VERSION ""

NS_ :

BS_:

BU_:
VAL_TABLE_ Write_Success 1 "Success" 0 "Not Written" ;
VAL_TABLE_ Read_Write 1 "Write" 0 "Read" ;

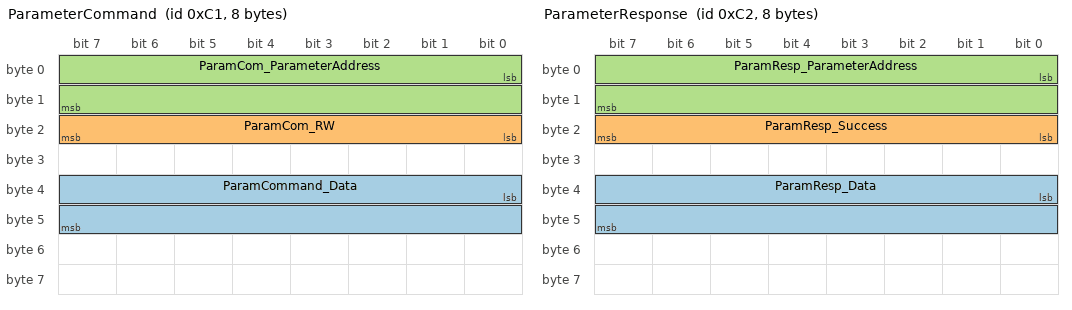
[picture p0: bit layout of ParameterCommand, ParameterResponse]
BO_ 193 ParameterCommand: 8 Vector__XXX
 SG_ ParamCommand_Data : 32|16@1+ (1,0) [0|65535] "" Vector__XXX
 SG_ ParamCom_RW : 16|8@1- (1,0) [0|1] "" Vector__XXX
 SG_ ParamCom_ParameterAddress : 0|16@1+ (1,0) [0|65535] "" Vector__XXX

BO_ 194 ParameterResponse: 8 Vector__XXX
 SG_ ParamResp_Data : 32|16@1+ (1,0) [0|65535] "" Vector__XXX
 SG_ ParamResp_Success : 16|8@1+ (1,0) [0|1] "" Vector__XXX
 SG_ ParamResp_ParameterAddress : 0|16@1+ (1,0) [0|65535] "" Vector__XXX

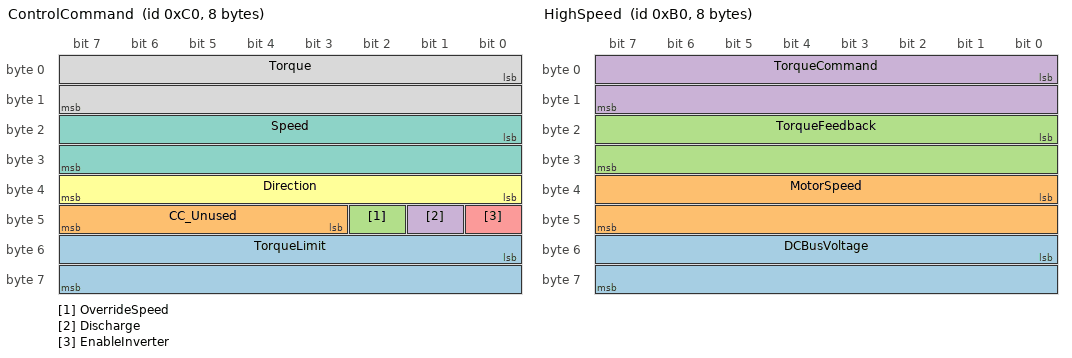
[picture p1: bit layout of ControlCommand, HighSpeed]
BO_ 192 ControlCommand: 8 Vector__XXX
 SG_ TorqueLimit : 48|16@1- (1,0) [-32768|32767] "0.1Nm" Vector__XXX
 SG_ CC_Unused : 43|5@1- (1,0) [0|0] "" Vector__XXX
 SG_ OverrideSpeed : 42|1@1+ (1,0) [0|1] "" Vector__XXX
 SG_ Discharge : 41|1@1+ (1,0) [0|1] "" Vector__XXX
 SG_ EnableInverter : 40|1@1+ (1,0) [0|1] "" Vector__XXX
 SG_ Direction : 32|8@1+ (1,0) [0|1] "" Vector__XXX
 SG_ Speed : 16|16@1- (1,0) [-32768|32767] "RPM" Vector__XXX
 SG_ Torque : 0|16@1- (1,0) [-32768|32767] "0.1Nm" Vector__XXX

BO_ 177 TorqueCapability: 8 Vector__XXX
 SG_ TorqueCapability : 0|16@1- (1,0) [-32768|32767] "0.1Nm" Vector__XXX

BO_ 176 HighSpeed: 8 Vector__XXX
 SG_ DCBusVoltage : 48|16@1- (1,0) [-32768|32767] "0.1V" Vector__XXX
 SG_ MotorSpeed : 32|16@1- (1,0) [-32768|32767] "RPM" Vector__XXX
 SG_ TorqueFeedback : 16|16@1- (1,0) [-32768|32767] "0.1Nm" Vector__XXX
 SG_ TorqueCommand : 0|16@1- (1,0) [-32768|32767] "0.1Nm" Vector__XXX

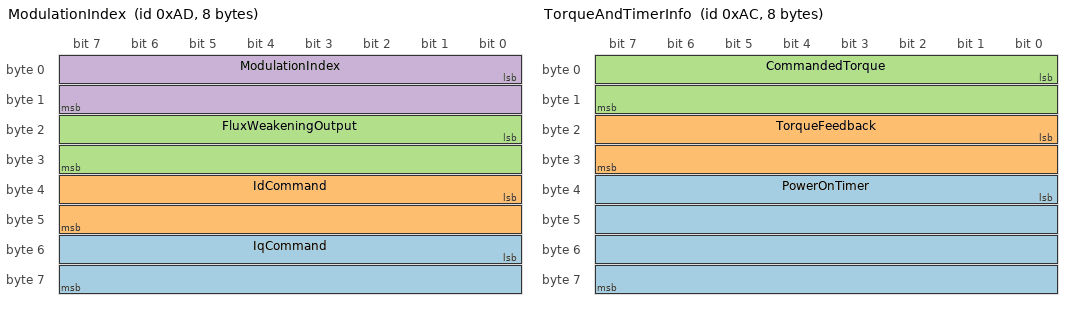
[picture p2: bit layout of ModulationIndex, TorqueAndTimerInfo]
BO_ 173 ModulationIndex: 8 Vector__XXX
 SG_ IqCommand : 48|16@1- (1,0) [-32768|32767] "0.1V" Vector__XXX
 SG_ IdCommand : 32|16@1- (1,0) [-32768|32767] "0.1V" Vector__XXX
 SG_ FluxWeakeningOutput : 16|16@1- (1,0) [-32768|32767] "0.1V" Vector__XXX
 SG_ ModulationIndex : 0|16@1- (1,0) [-32768|32767] "0.01x" Vector__XXX

BO_ 172 TorqueAndTimerInfo: 8 Vector__XXX
 SG_ PowerOnTimer : 32|32@1+ (1,0) [0|4294967295] "3ms" Vector__XXX
 SG_ TorqueFeedback : 16|16@1- (1,0) [-32768|32767] "0.1Nm" Vector__XXX
 SG_ CommandedTorque : 0|16@1- (1,0) [-32768|32767] "0.1Nm" Vector__XXX

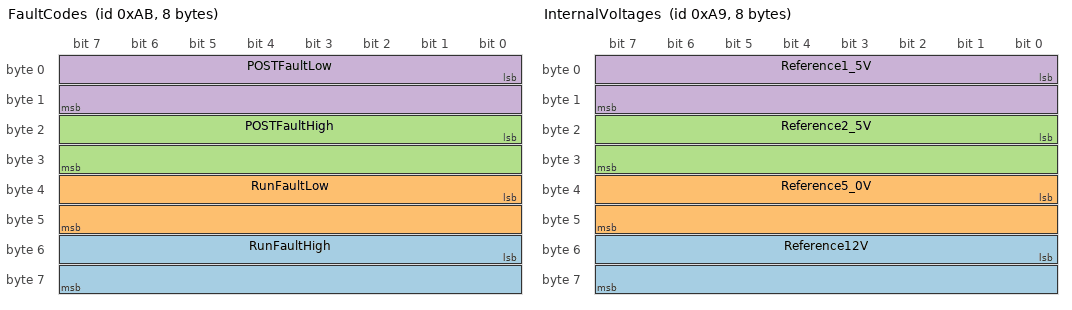
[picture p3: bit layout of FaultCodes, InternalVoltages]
BO_ 171 FaultCodes: 8 Vector__XXX
 SG_ RunFaultHigh : 48|16@1+ (1,0) [0|65535] "" Vector__XXX
 SG_ RunFaultLow : 32|16@1+ (1,0) [0|65535] "" Vector__XXX
 SG_ POSTFaultHigh : 16|16@1+ (1,0) [0|65535] "" Vector__XXX
 SG_ POSTFaultLow : 0|16@1+ (1,0) [0|65535] "" Vector__XXX

BO_ 169 InternalVoltages: 8 Vector__XXX
 SG_ Reference12V : 48|16@1- (1,0) [-32768|32767] "0.01V" Vector__XXX
 SG_ Reference5_0V : 32|16@1- (1,0) [-32768|32767] "0.01V" Vector__XXX
 SG_ Reference2_5V : 16|16@1- (1,0) [-32768|32767] "0.01V" Vector__XXX
 SG_ Reference1_5V : 0|16@1- (1,0) [-32768|32767] "0.01V" Vector__XXX

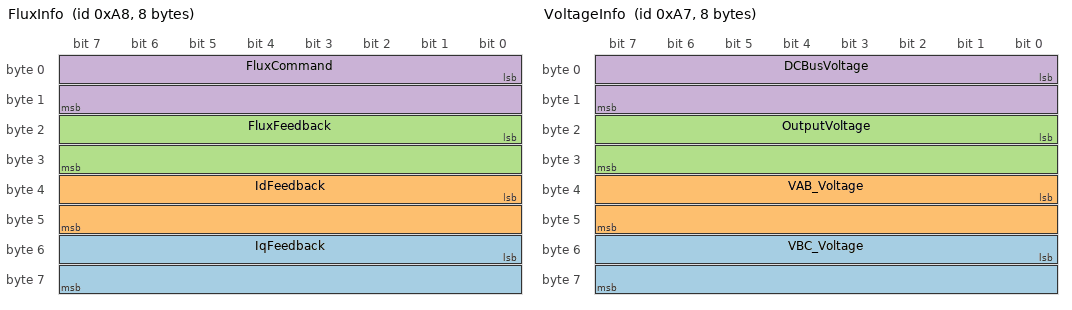
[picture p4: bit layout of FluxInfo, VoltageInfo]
BO_ 168 FluxInfo: 8 Vector__XXX
 SG_ IqFeedback : 48|16@1- (1,0) [-32768|32767] "0.1A" Vector__XXX
 SG_ IdFeedback : 32|16@1- (1,0) [-32768|32767] "0.1A" Vector__XXX
 SG_ FluxFeedback : 16|16@1- (1,0) [-32768|32767] "mWb" Vector__XXX
 SG_ FluxCommand : 0|16@1- (1,0) [-32768|32767] "mWb" Vector__XXX

BO_ 167 VoltageInfo: 8 Vector__XXX
 SG_ VBC_Voltage : 48|16@1- (1,0) [-32768|32767] "0.1V" Vector__XXX
 SG_ VAB_Voltage : 32|16@1- (1,0) [-32768|32767] "0.1V" Vector__XXX
 SG_ OutputVoltage : 16|16@1- (1,0) [-32768|32767] "0.1V" Vector__XXX
 SG_ DCBusVoltage : 0|16@1- (1,0) [-32768|32767] "0.1V" Vector__XXX

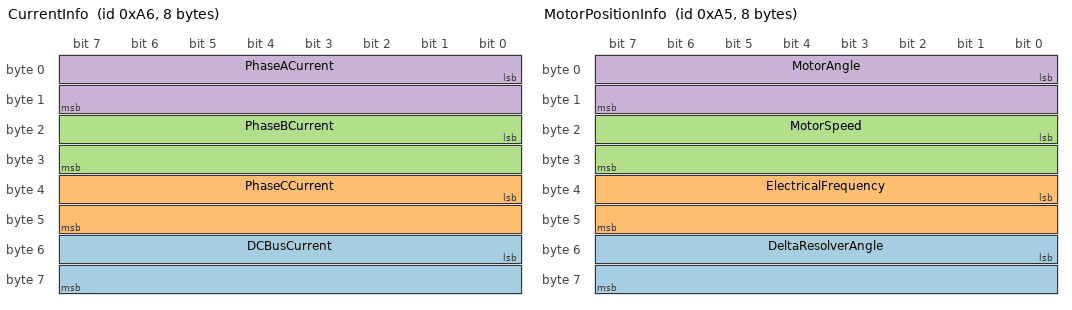
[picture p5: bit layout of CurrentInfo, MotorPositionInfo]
BO_ 166 CurrentInfo: 8 Vector__XXX
 SG_ DCBusCurrent : 48|16@1- (1,0) [-32768|32767] "0.1A" Vector__XXX
 SG_ PhaseCCurrent : 32|16@1- (1,0) [-32768|32767] "0.1A" Vector__XXX
 SG_ PhaseBCurrent : 16|16@1- (1,0) [-32768|32767] "0.1A" Vector__XXX
 SG_ PhaseACurrent : 0|16@1- (1,0) [-32768|32767] "0.1A" Vector__XXX

BO_ 165 MotorPositionInfo: 8 Vector__XXX
 SG_ DeltaResolverAngle : 48|16@1- (1,0) [-32768|32767] "0.1deg" Vector__XXX
 SG_ ElectricalFrequency : 32|16@1- (1,0) [-32768|32767] "0.1Hz" Vector__XXX
 SG_ MotorSpeed : 16|16@1- (1,0) [-32768|32767] "RPM" Vector__XXX
 SG_ MotorAngle : 0|16@1- (1,0) [-32768|32767] "0.1deg" Vector__XXX

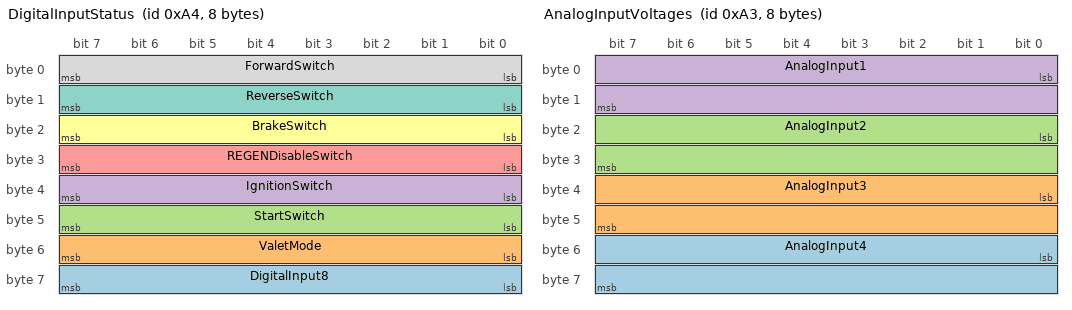
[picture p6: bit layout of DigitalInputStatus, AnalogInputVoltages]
BO_ 164 DigitalInputStatus: 8 Vector__XXX
 SG_ DigitalInput8 : 56|8@1+ (1,0) [0|1] "" Vector__XXX
 SG_ ValetMode : 48|8@1+ (1,0) [0|1] "" Vector__XXX
 SG_ StartSwitch : 40|8@1+ (1,0) [0|1] "" Vector__XXX
 SG_ IgnitionSwitch : 32|8@1+ (1,0) [0|1] "" Vector__XXX
 SG_ REGENDisableSwitch : 24|8@1+ (1,0) [0|1] "" Vector__XXX
 SG_ BrakeSwitch : 16|8@1+ (1,0) [0|1] "" Vector__XXX
 SG_ ReverseSwitch : 8|8@1+ (1,0) [0|1] "" Vector__XXX
 SG_ ForwardSwitch : 0|8@1+ (1,0) [0|1] "" Vector__XXX

BO_ 163 AnalogInputVoltages: 8 Vector__XXX
 SG_ AnalogInput4 : 48|16@1- (1,0) [-32768|32767] "" Vector__XXX
 SG_ AnalogInput3 : 32|16@1- (1,0) [-32768|32767] "" Vector__XXX
 SG_ AnalogInput2 : 16|16@1- (1,0) [-32768|32767] "" Vector__XXX
 SG_ AnalogInput1 : 0|16@1- (1,0) [-32768|32767] "" Vector__XXX

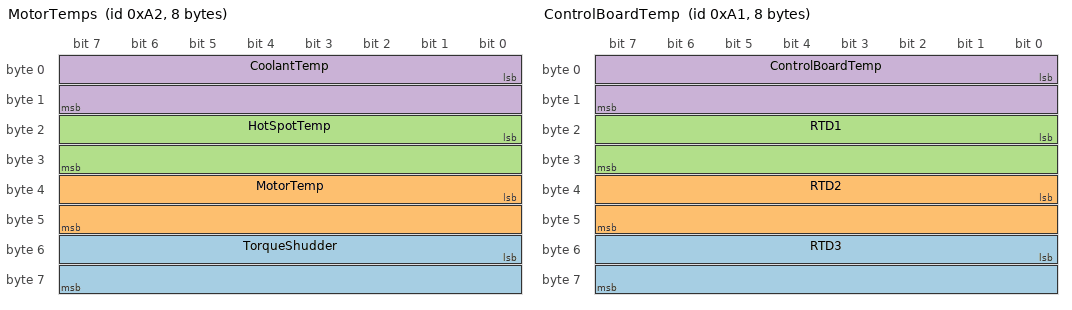
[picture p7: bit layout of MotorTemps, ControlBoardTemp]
BO_ 162 MotorTemps: 8 Vector__XXX
 SG_ TorqueShudder : 48|16@1- (1,0) [-32768|32767] "" Vector__XXX
 SG_ MotorTemp : 32|16@1- (1,0) [-32768|32767] "" Vector__XXX
 SG_ HotSpotTemp : 16|16@1- (1,0) [-32768|32767] "" Vector__XXX
 SG_ CoolantTemp : 0|16@1- (1,0) [-32768|32767] "" Vector__XXX

BO_ 161 ControlBoardTemp: 8 Vector__XXX
 SG_ RTD3 : 48|16@1- (1,0) [-32768|32767] "" Vector__XXX
 SG_ RTD2 : 32|16@1- (1,0) [-32768|32767] "" Vector__XXX
 SG_ RTD1 : 16|16@1- (1,0) [-32768|32767] "" Vector__XXX
 SG_ ControlBoardTemp : 0|16@1- (1,0) [-32768|32767] "" Vector__XXX

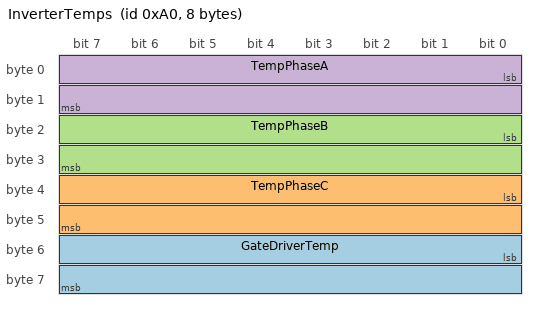
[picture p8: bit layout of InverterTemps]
BO_ 160 InverterTemps: 8 Vector__XXX
 SG_ GateDriverTemp : 48|16@1- (1,0) [-32768|32767] "" Vector__XXX
 SG_ TempPhaseC : 32|16@1- (1,0) [-32768|32767] "" Vector__XXX
 SG_ TempPhaseB : 16|16@1- (1,0) [-32768|32767] "" Vector__XXX
 SG_ TempPhaseA : 0|16@1- (1,0) [-32768|32767] "" Vector__XXX

BO_ 6 TireTemperature: 7 Vector__XXX
 SG_ RearRight_Temp_Mid m3 : 40|16@1- (1,0) [-32768|32767] "" Vector__XXX
 SG_ RearRight_Temp_Out m3 : 24|16@1- (1,0) [-32768|32767] "" Vector__XXX
 SG_ RearLeft_Temp_Mid m2 : 40|16@1- (1,0) [-32768|32767] "" Vector__XXX
 SG_ RearLeft_Temp_Out m2 : 24|16@1- (1,0) [-32768|32767] "" Vector__XXX
 SG_ FrontRight_Temp_Mid m1 : 40|16@1- (1,0) [-32768|32767] "" Vector__XXX
 SG_ FrontRight_Temp_Out m1 : 24|16@1- (1,0) [-32768|32767] "" Vector__XXX
 SG_ FrontLeft_Temp_Mid m0 : 40|16@1- (1,0) [-32768|32767] "" Vector__XXX
 SG_ FrontLeft_Temp_Out m0 : 24|16@1- (1,0) [-32768|32767] "" Vector__XXX
 SG_ RearRight_Temp_In m3 : 8|16@1- (1,0) [-32768|32767] "" Vector__XXX
 SG_ RearLeft_Temp_In m2 : 8|16@1- (1,0) [-32768|32767] "" Vector__XXX
 SG_ FrontRight_Temp_In m1 : 8|16@1- (1,0) [-32768|32767] "" Vector__XXX
 SG_ FrontLeft_Temp_In m0 : 8|16@1- (1,0) [-32768|32767] "" Vector__XXX
 SG_ TireTemperature_MultiPlex M : 0|8@1+ (1,0) [0|3] "" Vector__XXX

BO_ 5 TireRPM: 5 Vector__XXX
 SG_ RearRight m3 : 8|32@1- (1,0) [-3.4E+38|3.4E+38] "" Vector__XXX
 SG_ RearLeft m2 : 8|32@1- (1,0) [-3.4E+38|3.4E+38] "" Vector__XXX
 SG_ FrontRight m1 : 8|32@1- (1,0) [-3.4E+38|3.4E+38] "" Vector__XXX
 SG_ FrontLeft m0 : 8|32@1- (1,0) [-3.4E+38|3.4E+38] "" Vector__XXX
 SG_ TireRPM_MultiPlex M : 0|8@1+ (1,0) [0|3] "" Vector__XXX

BO_ 4 RVC: 5 Vector__XXX
 SG_ Y_Rotation m4 : 8|32@1- (1,0) [-3.4E+38|3.4E+38] "" Vector__XXX
 SG_ Z_Rotation m5 : 8|32@1- (1,0) [-3.4E+38|3.4E+38] "" Vector__XXX
 SG_ X_Rotation m3 : 8|32@1- (1,0) [-3.4E+38|3.4E+38] "" Vector__XXX
 SG_ Z_Acceleration m2 : 8|32@1- (1,0) [-3.4E+38|3.4E+38] "" Vector__XXX
 SG_ Y_Acceleration m1 : 8|32@1- (1,0) [-3.4E+38|3.4E+38] "" Vector__XXX
 SG_ X_Acceleration m0 : 8|32@1- (1,0) [-3.4E+38|3.4E+38] "" Vector__XXX
 SG_ RVC_MultiPlex M : 0|8@1+ (1,0) [0|5] "" Vector__XXX

BO_ 9 GPS: 8 Vector__XXX
 SG_ GPSLatitude : 32|32@1- (1,0) [-2147483648|2147483647] "" Vector__XXX
 SG_ GPSLongitude : 0|32@1- (1,32) [-2147483616|2147483679] "" Vector__XXX

BO_ 0 StartSwitch: 1 Vector__XXX
 SG_ StartSwitch : 0|8@1+ (1,0) [0|1] "" Vector__XXX

BO_ 1 Throttle1Position: 2 Vector__XXX
 SG_ Throttle1Position : 0|16@1+ (1,0) [0|65535] "" Vector__XXX

BO_ 2 Throttle2Position: 2 Vector__XXX
 SG_ Throttle2Position : 0|16@1+ (1,0) [0|65535] "" Vector__XXX

BO_ 3 BrakePressure: 2 Vector__XXX
 SG_ Brake : 0|16@1+ (1,0) [0|65535] "" Vector__XXX

CM_ SG_ 1 Throttle1Position "throttle 1 pos sensor";
CM_ SG_ 2 Throttle2Position "Throttle 2 pos sensor";
CM_ SG_ 3 Brake "Brake sensor";
BA_DEF_  "BusType" STRING ;
BA_DEF_DEF_  "BusType" "CAN";
VAL_ 193 ParamCom_RW 1 "Write" 0 "Read" ;
VAL_ 194 ParamResp_Success 1 "Success" 0 "Not Written" ;
SIG_VALTYPE_ 5 RearRight : 1;
SIG_VALTYPE_ 5 RearLeft : 1;
SIG_VALTYPE_ 5 FrontRight : 1;
SIG_VALTYPE_ 5 FrontLeft : 1;
SIG_VALTYPE_ 4 Y_Rotation : 1;
SIG_VALTYPE_ 4 Z_Rotation : 1;
SIG_VALTYPE_ 4 X_Rotation : 1;
SIG_VALTYPE_ 4 Z_Acceleration : 1;
SIG_VALTYPE_ 4 Y_Acceleration : 1;
SIG_VALTYPE_ 4 X_Acceleration : 1;
